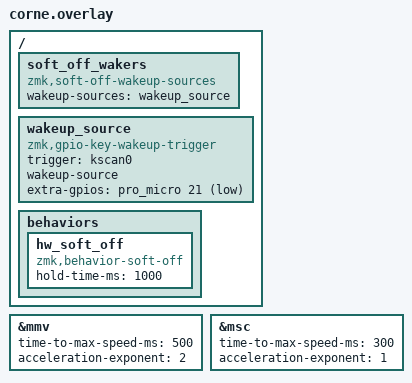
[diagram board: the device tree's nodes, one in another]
/*
 * Copyright (c) 2020 The ZMK Contributors
 *
 * SPDX-License-Identifier: MIT
 */

/ {
    soft_off_wakers {
        compatible = "zmk,soft-off-wakeup-sources";
        wakeup-sources = <&wakeup_source>;
    };

    wakeup_source: wakeup_source {
        compatible = "zmk,gpio-key-wakeup-trigger";

        trigger = <&kscan0>;
        wakeup-source;
        extra-gpios
            = <&pro_micro 21 GPIO_ACTIVE_LOW>  // Top left key (TAB position, matrix 0,0)
            ;
    };

    behaviors {
        hw_soft_off: hw_soft_off {
            compatible = "zmk,behavior-soft-off";
            #binding-cells = <0>;
            hold-time-ms = <1000>;  // Must hold for 1 second to trigger soft-off
        };
    };
};

// Advanced mouse emulation configuration
&mmv {
    time-to-max-speed-ms = <500>;
    acceleration-exponent = <2>;
};

&msc {
    time-to-max-speed-ms = <300>;
    acceleration-exponent = <1>;
};
